# FUSB15200 register map
Vendor: ON Semiconductor; Series: FUSB15200; File version: 1.0
CPU: CM0+ r1p0, little endian, no MPU, no FPU, 3 interrupt priority bits
Registers are 32-bit, read-write, reset 0x0 unless marked. A register's access mark holds for its fields unless they carry their own. Offsets are from the block's base; [hi:lo] are bit positions.

## I2C_Port_3
Base 0x40E00000
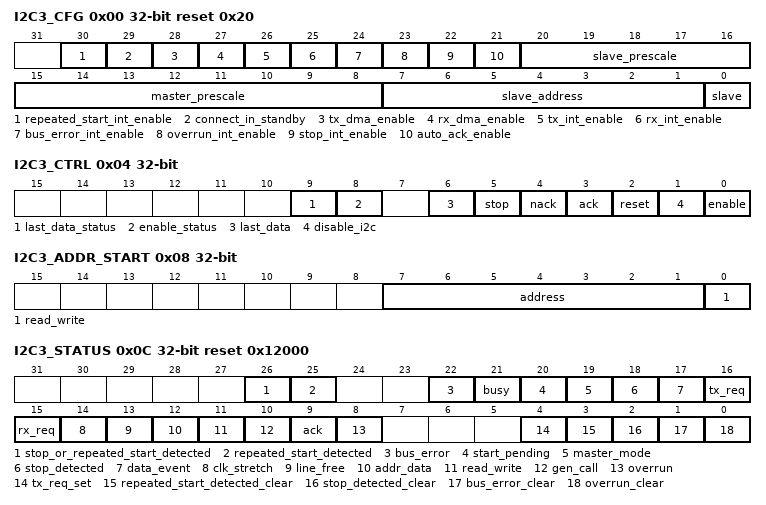
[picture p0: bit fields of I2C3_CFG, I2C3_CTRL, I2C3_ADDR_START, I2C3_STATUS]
0x00 I2C3_CFG reset 0x20 (reset mask 0x7FE10103)
  [30] repeated_start_int_enable, [29] connect_in_standby, [28] tx_dma_enable, [27] rx_dma_enable, [26] tx_int_enable, [25] rx_int_enable, [24] bus_error_int_enable, [23] overrun_int_enable, [22] stop_int_enable, [21] auto_ack_enable, [20:16] slave_prescale, [15:8] master_prescale, [7:1] slave_address, [0] slave
0x04 I2C3_CTRL
  [9] last_data_status ro, [8] enable_status ro, [6] last_data wo, [5] stop wo, [4] nack wo, [3] ack wo, [2] reset wo, [1] disable_i2c wo, [0] enable wo
0x08 I2C3_ADDR_START (reset mask 0x3)
  [7:1] address, [0] read_write
0x0C I2C3_STATUS reset 0x12000
  [26] stop_or_repeated_start_detected ro, [25] repeated_start_detected ro, [22] bus_error ro, [21] busy ro, [20] start_pending ro, [19] master_mode ro, [18] stop_detected ro, [17] data_event ro, [16] tx_req ro, [15] rx_req ro, [14] clk_stretch ro, [13] line_free ro, [12] addr_data ro, [11] read_write ro, [10] gen_call ro, [9] ack ro, [8] overrun ro, [4] tx_req_set wo, [3] repeated_start_detected_clear wo, [2] stop_detected_clear wo, [1] bus_error_clear wo, [0] overrun_clear wo
0x10 I2C3_TX_DATA (reset mask 0x1)
  [7:0] tx_data
0x14 I2C3_RX_DATA (reset mask 0x1)
  [7:0] rx_data ro
0x18 I2C3_RX_DATA_MIRROR (reset mask 0x1)
  [7:0] rx_data ro
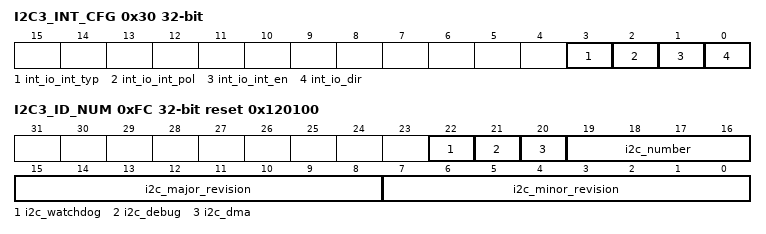
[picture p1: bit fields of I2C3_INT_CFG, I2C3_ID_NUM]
0x30 I2C3_INT_CFG
  [3] int_io_int_typ, [2] int_io_int_pol, [1] int_io_int_en, [0] int_io_dir
0x34 I2C3_INT_OUT reset 0x1
  [0] int_out
0x38 I2C3_INT_IN
  [0] int_in ro
0x3C I2C3_INT_STS
  [0] int_sts wo
0xFC I2C3_ID_NUM reset 0x120100 (reset mask 0x710101)
  [22] i2c_watchdog ro, [21] i2c_debug ro, [20] i2c_dma ro, [19:16] i2c_number ro, [15:8] i2c_major_revision ro, [7:0] i2c_minor_revision ro

## I2C_Port_4
Base 0x40F00000
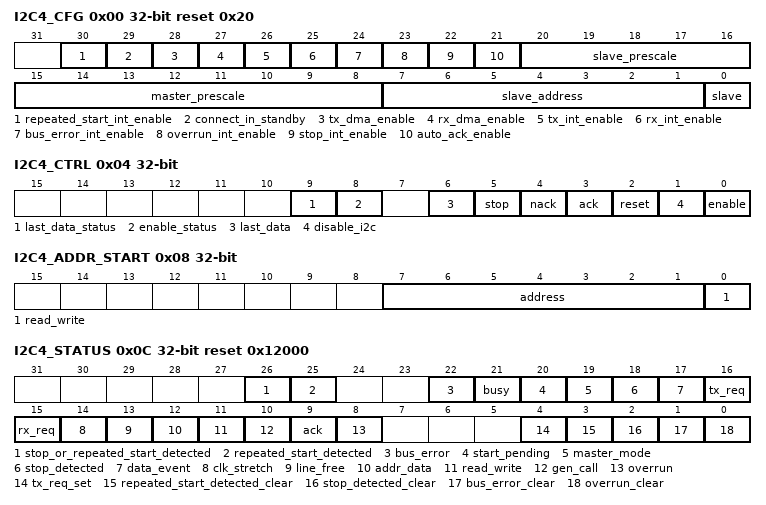
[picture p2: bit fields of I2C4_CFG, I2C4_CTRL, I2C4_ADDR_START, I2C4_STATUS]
0x00 I2C4_CFG reset 0x20 (reset mask 0x7FE10103)
  [30] repeated_start_int_enable, [29] connect_in_standby, [28] tx_dma_enable, [27] rx_dma_enable, [26] tx_int_enable, [25] rx_int_enable, [24] bus_error_int_enable, [23] overrun_int_enable, [22] stop_int_enable, [21] auto_ack_enable, [20:16] slave_prescale, [15:8] master_prescale, [7:1] slave_address, [0] slave
0x04 I2C4_CTRL
  [9] last_data_status ro, [8] enable_status ro, [6] last_data wo, [5] stop wo, [4] nack wo, [3] ack wo, [2] reset wo, [1] disable_i2c wo, [0] enable wo
0x08 I2C4_ADDR_START (reset mask 0x3)
  [7:1] address, [0] read_write
0x0C I2C4_STATUS reset 0x12000
  [26] stop_or_repeated_start_detected ro, [25] repeated_start_detected ro, [22] bus_error ro, [21] busy ro, [20] start_pending ro, [19] master_mode ro, [18] stop_detected ro, [17] data_event ro, [16] tx_req ro, [15] rx_req ro, [14] clk_stretch ro, [13] line_free ro, [12] addr_data ro, [11] read_write ro, [10] gen_call ro, [9] ack ro, [8] overrun ro, [4] tx_req_set wo, [3] repeated_start_detected_clear wo, [2] stop_detected_clear wo, [1] bus_error_clear wo, [0] overrun_clear wo
0x10 I2C4_TX_DATA (reset mask 0x1)
  [7:0] tx_data
0x14 I2C4_RX_DATA (reset mask 0x1)
  [7:0] rx_data ro
0x18 I2C4_RX_DATA_MIRROR (reset mask 0x1)
  [7:0] rx_data ro
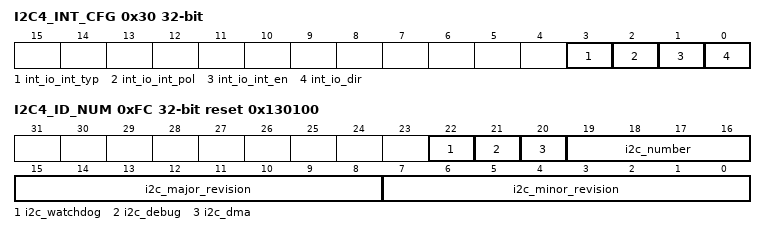
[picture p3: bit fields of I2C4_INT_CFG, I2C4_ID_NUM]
0x30 I2C4_INT_CFG
  [3] int_io_int_typ, [2] int_io_int_pol, [1] int_io_int_en, [0] int_io_dir
0x34 I2C4_INT_OUT reset 0x1
  [0] int_out
0x38 I2C4_INT_IN
  [0] int_in ro
0x3C I2C4_INT_STS
  [0] int_sts wo
0xFC I2C4_ID_NUM reset 0x130100 (reset mask 0x710101)
  [22] i2c_watchdog ro, [21] i2c_debug ro, [20] i2c_dma ro, [19:16] i2c_number ro, [15:8] i2c_major_revision ro, [7:0] i2c_minor_revision ro

## USB_Type_C_PD_Port_A
Base 0x41900000
Same registers: USB_Type_C_PD_Port_B 0x41A00000
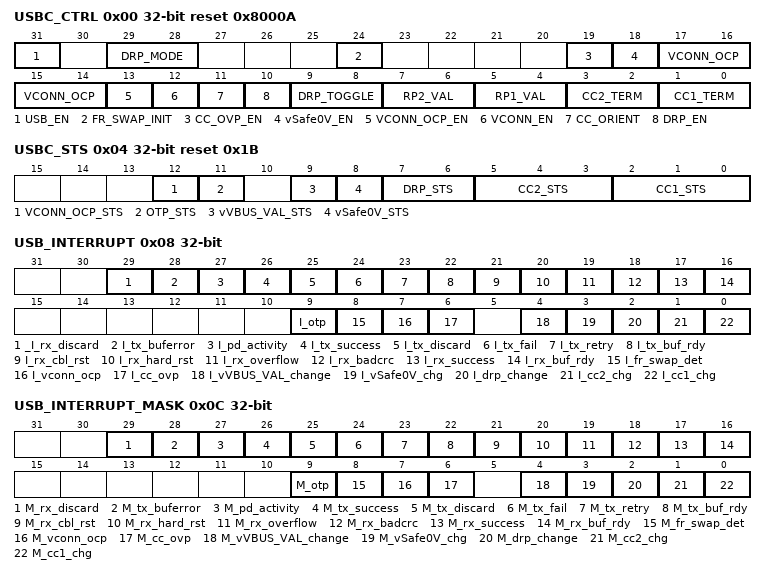
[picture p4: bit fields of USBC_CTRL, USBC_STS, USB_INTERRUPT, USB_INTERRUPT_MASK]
0x00 USBC_CTRL reset 0x8000A (reset mask 0x910C7D55)
  [31] USB_EN, [29:28] DRP_MODE, [24] FR_SWAP_INIT wo, [19] CC_OVP_EN, [18] vSafe0V_EN, [17:14] VCONN_OCP, [13] VCONN_OCP_EN, [12] VCONN_EN, [11] CC_ORIENT, [10] DRP_EN, [9:8] DRP_TOGGLE, [7:6] RP2_VAL, [5:4] RP1_VAL, [3:2] CC2_TERM, [1:0] CC1_TERM
0x04 USBC_STS reset 0x1B (reset mask 0x1B49)
  [12] VCONN_OCP_STS ro, [11] OTP_STS ro, [9] vVBUS_VAL_STS ro, [8] vSafe0V_STS ro, [7:6] DRP_STS ro, [5:3] CC2_STS ro, [2:0] CC1_STS ro
0x08 USB_INTERRUPT
  [29] _I_rx_discard wo, [28] I_tx_buferror wo, [27] I_pd_activity wo, [26] I_tx_success wo, [25] I_tx_discard wo, [24] I_tx_fail wo, [23] I_tx_retry wo, [22] I_tx_buf_rdy wo, [21] I_rx_cbl_rst wo, [20] I_rx_hard_rst wo, [19] I_rx_overflow wo, [18] I_rx_badcrc wo, [17] I_rx_success wo, [16] I_rx_buf_rdy wo, [9] I_otp wo, [8] I_fr_swap_det wo, [7] I_vconn_ocp wo, [6] I_cc_ovp wo, [4] I_vVBUS_VAL_change wo, [3] I_vSafe0V_chg wo, [2] I_drp_change wo, [1] I_cc2_chg wo, [0] I_cc1_chg wo
0x0C USB_INTERRUPT_MASK
  [29] M_rx_discard, [28] M_tx_buferror, [27] M_pd_activity, [26] M_tx_success, [25] M_tx_discard, [24] M_tx_fail, [23] M_tx_retry, [22] M_tx_buf_rdy, [21] M_rx_cbl_rst, [20] M_rx_hard_rst, [19] M_rx_overflow, [18] M_rx_badcrc, [17] M_rx_success, [16] M_rx_buf_rdy, [9] M_otp, [8] M_fr_swap_det, [7] M_vconn_ocp, [6] M_cc_ovp, [4] M_vVBUS_VAL_change, [3] M_vSafe0V_chg, [2] M_drp_change, [1] M_cc2_chg, [0] M_cc1_chg
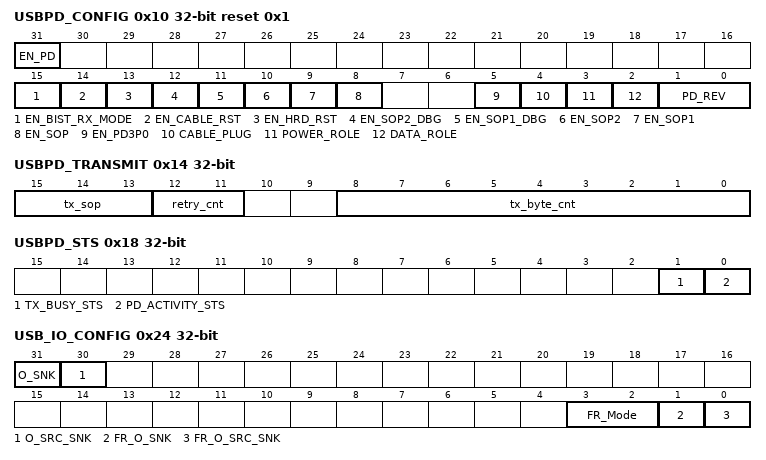
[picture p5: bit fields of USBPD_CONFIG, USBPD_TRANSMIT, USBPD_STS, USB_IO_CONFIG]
0x10 USBPD_CONFIG reset 0x1 (reset mask 0x8000FF3D)
  [31] EN_PD, [15] EN_BIST_RX_MODE, [14] EN_CABLE_RST, [13] EN_HRD_RST, [12] EN_SOP2_DBG, [11] EN_SOP1_DBG, [10] EN_SOP2, [9] EN_SOP1, [8] EN_SOP, [5] EN_PD3P0, [4] CABLE_PLUG, [3] POWER_ROLE, [2] DATA_ROLE, [1:0] PD_REV
0x14 USBPD_TRANSMIT (reset mask 0x2801)
  [15:13] tx_sop wo, [12:11] retry_cnt wo, [8:0] tx_byte_cnt wo
0x18 USBPD_STS
  [1] TX_BUSY_STS ro, [0] PD_ACTIVITY_STS ro
0x1C USBPD_DATA_TX (reset mask 0x1)
0x20 USBPD_DATA_RX (reset mask 0x1)
  [31:0] USBPD_DATA_RX ro
0x24 USB_IO_CONFIG (reset mask 0xC0000007)
  [31] O_SNK, [30] O_SRC_SNK, [3:2] FR_Mode, [1] FR_O_SNK, [0] FR_O_SRC_SNK
0x28 VBUS_CTRL (reset mask 0x1)
  [2:0] VBUS_DISCH_SEL
0x2C USBPD_MSG_HEADER (reset mask 0x1)
  [15:0] MSG_HEADER
